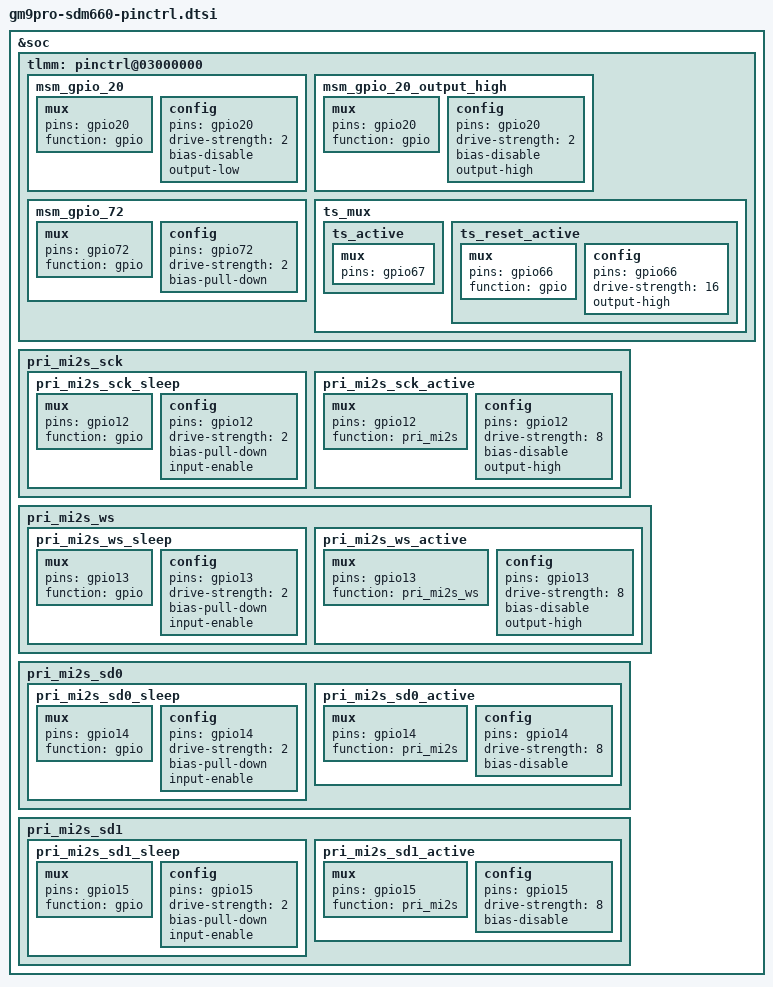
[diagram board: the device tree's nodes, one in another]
&soc {
	tlmm: pinctrl@03000000 {
		/* add msm_gpio_20 & msm_gpio_72 for fpc1020 */
		msm_gpio_20: msm_gpio_20 {
			mux {
				pins = "gpio20";
				function = "gpio";
			};

			config {
				pins = "gpio20";
				drive-strength = <2>;
				bias-disable;
				output-low;
			};
		};

		msm_gpio_20_output_high: msm_gpio_20_output_high {
			mux {
				pins = "gpio20";
				function = "gpio";
			};

			config {
				pins = "gpio20";
				drive-strength = <2>;
				bias-disable;
				output-high;
			};
		};

		msm_gpio_72: msm_gpio_72 {
			mux {
				pins = "gpio72";
				function = "gpio";
			};

			config {
				pins = "gpio72";
				drive-strength = <2>;
				bias-pull-down;
			};
		};

                /* for sec_ts */
		ts_mux {
			ts_active {
				mux {
					pins = "gpio67";
				};
			};

			ts_reset_active: ts_reset_active {
				mux {
					pins = "gpio66";
					function = "gpio";
				};

				config {
					pins = "gpio66";
					drive-strength = <16>;
					output-high;
				};
			};
		};
	};

                /* add pri_mi2s for tfa98xx smartpa */
		pri_mi2s_sck {
			pri_mi2s_sck_sleep: pri_mi2s_sck_sleep {
			    mux {
				pins = "gpio12";
				function = "gpio";
			    };

			    config {
				pins = "gpio12";
				drive-strength = <2>;   /* 2 mA */
				bias-pull-down;         /* PULL DOWN */
				input-enable;
			    };
			};

			pri_mi2s_sck_active: pri_mi2s_sck_active {
			    mux {
				pins = "gpio12";
				function = "pri_mi2s";
			    };

			    config {
				pins = "gpio12";
				drive-strength = <8>;   /* 8 mA */
				bias-disable;           /* NO PULL */
				output-high;
			    };
			};
		};

		pri_mi2s_ws {
			pri_mi2s_ws_sleep: pri_mi2s_ws_sleep {
			    mux {
				    pins = "gpio13";
				    function = "gpio";
			    };

			    config {
				    pins = "gpio13";
				    drive-strength = <2>;   /* 2 mA */
				    bias-pull-down;         /* PULL DOWN */
				    input-enable;
			    };
			};

			pri_mi2s_ws_active: pri_mi2s_ws_active {
			    mux {
				    pins = "gpio13";
				    function = "pri_mi2s_ws";
			    };

			    config {
				    pins = "gpio13";
				    drive-strength = <8>;   /* 8 mA */
				    bias-disable;           /* NO PULL */
				    output-high;
			    };
			};
		};

		pri_mi2s_sd0 {
			pri_mi2s_sd0_sleep: pri_mi2s_sd0_sleep {
			    mux {
				    pins = "gpio14";
				    function = "gpio";
			    };

			    config {
				    pins = "gpio14";
				    drive-strength = <2>;   /* 2 mA */
				    bias-pull-down;         /* PULL DOWN */
				    input-enable;
			    };
			};

			pri_mi2s_sd0_active: pri_mi2s_sd0_active {
			    mux {
				    pins = "gpio14";
				    function = "pri_mi2s";
			    };

			    config {
				    pins = "gpio14";
				    drive-strength = <8>;   /* 8 mA */
				    bias-disable;           /* NO PULL */
			    };
			};
		};

		pri_mi2s_sd1 {
			pri_mi2s_sd1_sleep: pri_mi2s_sd1_sleep {
			    mux {
				    pins = "gpio15";
				    function = "gpio";
			    };

			    config {
				    pins = "gpio15";
				    drive-strength = <2>;   /* 2 mA */
				    bias-pull-down;         /* PULL DOWN */
				    input-enable;
			    };
			};

			pri_mi2s_sd1_active: pri_mi2s_sd1_active {
				mux {
					pins = "gpio15";
					function = "pri_mi2s";
				};

				config {
					pins = "gpio15";
					drive-strength = <8>;   /* 8 mA */
					bias-disable;           /* NO PULL */
				};
			};
		};
};
